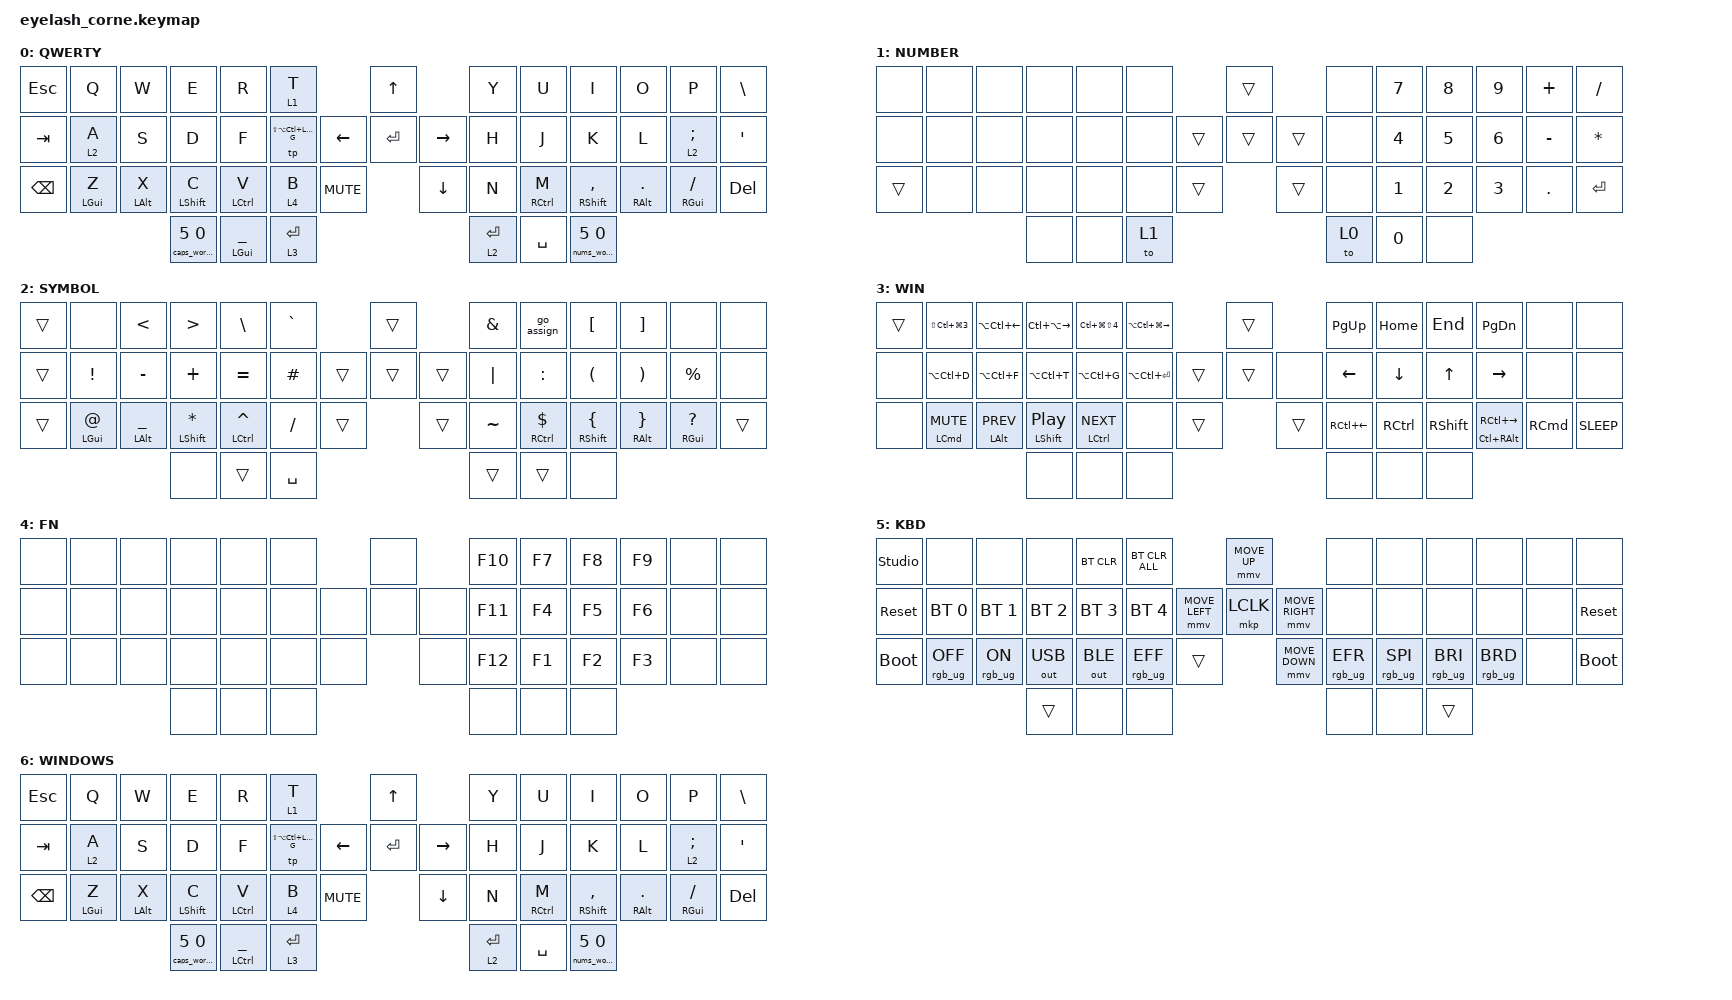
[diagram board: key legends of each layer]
#include "corne_common.dtsi"


    behaviors {
        // Override HMR and HML to add board-specific hold-trigger-key-positions
        HMR: HMR {
            compatible = "zmk,behavior-hold-tap";
            label = "HMR";
            bindings = <&kp>, <&kp>;
            #binding-cells = <2>;
            tapping-term-ms = <200>;
            quick-tap-ms = <175>;
            flavor = "tap-preferred";
            hold-trigger-key-positions = <0 1 2 3 4 5 13 14 15 16 17 18 28 29 30 31 32 33 42 43 44 45 46 47>;
            hold-trigger-on-release;
            require-prior-idle-ms = <150>;
        };

        HML: HML {
            compatible = "zmk,behavior-hold-tap";
            label = "HML";
            bindings = <&kp>, <&kp>;
            #binding-cells = <2>;
            tapping-term-ms = <200>;
            quick-tap-ms = <175>;
            flavor = "tap-preferred";
            hold-trigger-key-positions = <7 8 10 11 12 22 23 24 25 26 27 36 37 38 39 40 41 46 47 45 42 43 44>;
            hold-trigger-on-release;
            require-prior-idle-ms = <150>;
        };
    };

    keymap {
        compatible = "zmk,keymap";

        default_layer {
            display-name = "QWERTY";
            bindings = <
&kp ESCAPE     &kp Q            &kp W            &kp E              &kp R                    &lt 1 T                                             &kp UP                &kp Y        &kp U                 &kp I                   &kp O                  &kp P                 &kp BACKSLASH
&kp TAB        &lt 2 A          &kp S            &kp D              &kp F                    &tp LS(LA(LC(LEFT_GUI))) G                &kp LEFT  &kp ENTER  &kp RIGHT  &kp H        &kp J                 &kp K                   &kp L                  &lt 2 SEMICOLON       &kp SQT
&kp BACKSPACE  &HML LEFT_GUI Z  &HML LEFT_ALT X  &HML LEFT_SHIFT C  &HML LCTRL V             &lt 4 B                     &kp C_MUTE              &kp DOWN              &kp N        &HMR RIGHT_CONTROL M  &HMR RIGHT_SHIFT COMMA  &HMR RIGHT_ALT PERIOD  &HMR RIGHT_GUI SLASH  &kp DELETE
                                                 &caps_word_mo 5 0  &mt LEFT_GUI UNDERSCORE  &lt 3 ENTER                                                               &lt 2 ENTER  &kp SPACE             &nums_word_mo 5 0
            >;

        };

        number {
            bindings = <
&none   &none  &none  &none  &none  &none                    &trans          &none  &kp N7        &kp N8        &kp N9        &kp PLUS    &kp SLASH
&none   &none  &none  &none  &none  &none            &trans  &trans  &trans  &none  &kp NUMBER_4  &kp N5        &kp NUMBER_6  &kp MINUS   &kp ASTERISK
&trans  &none  &none  &none  &none  &none  &trans            &trans          &none  &kp NUMBER_1  &kp NUMBER_2  &kp NUMBER_3  &kp PERIOD  &kp ENTER
                      &none  &none  &to 1                                    &to 0  &kp N0        &none
            >;

            label = "NUMBER";
        };

        symbol {
            bindings = <
&trans  &none             &kp LESS_THAN    &kp GREATER_THAN      &kp BACKSLASH     &kp GRAVE                    &trans          &kp AMPS   &go_assign               &kp LEFT_BRACKET             &kp RIGHT_BRACKET      &none                    &none
&trans  &kp EXCLAMATION   &kp MINUS        &kp PLUS              &kp EQUAL         &kp POUND            &trans  &trans  &trans  &kp PIPE   &kp COLON                &kp LEFT_PARENTHESIS         &kp RIGHT_PARENTHESIS  &kp PERCENT              &none
&trans  &HML LEFT_GUI AT  &HML LALT UNDER  &HML LSHIFT ASTERISK  &HML LCTRL CARET  &kp SLASH  &trans            &trans          &kp TILDE  &HMR RIGHT_CONTROL DLLR  &HMR RIGHT_SHIFT LEFT_BRACE  &HMR RALT RIGHT_BRACE  &HMR RIGHT_GUI QUESTION  &trans
                                           &none                 &trans            &kp SPACE                                    &trans     &trans                   &none
            >;

            label = "SYMBOL";
        };

        win {
            bindings = <
&trans  &kp LS(LC(LG(NUMBER_3)))  &kp LA(LC(LEFT))      &kp LC(LA(RIGHT))             &kp LC(LG(LS(NUMBER_4)))  &kp LA(LC(LG(RIGHT)))                    &trans         &kp PAGE_UP   &kp HOME        &kp END       &kp PAGE_DOWN                 &none     &none
&none   &kp LA(LC(D))             &kp LA(LC(F))         &kp LA(LC(T))                 &kp LA(LC(G))             &kp LA(LC(ENTER))                &trans  &trans  &none  &kp LEFT      &kp DOWN_ARROW  &kp UP_ARROW  &kp RIGHT                     &none     &none
&none   &HML LCMD C_MUTE          &HML LEFT_ALT C_PREV  &HML LEFT_SHIFT C_PLAY_PAUSE  &HML LCTRL C_NEXT         &none                  &trans            &trans         &kp RC(LEFT)  &kp RCTRL       &kp RSHIFT    &HMR LC(RIGHT_ALT) RC(RIGHT)  &kp RCMD  &kp C_SLEEP
                                                        &none                         &none                     &none                                                   &none         &none           &none
            >;

            label = "WIN";
        };

        function {
            bindings = <
&none  &none  &none  &none  &none  &none                  &none         &kp F10  &kp F7  &kp F8  &kp F9  &none  &none
&none  &none  &none  &none  &none  &none           &none  &none  &none  &kp F11  &kp F4  &kp F5  &kp F6  &none  &none
&none  &none  &none  &none  &none  &none  &none           &none         &kp F12  &kp F1  &kp F2  &kp F3  &none  &none
                     &none  &none  &none                                &none    &none   &none
            >;

            label = "FN";
        };

        kbd_ctl {
            display-name = "KBD";
            bindings = <
&studio_unlock  &none            &none           &none         &bt BT_CLR    &bt BT_CLR_ALL                             &mmv MOVE_UP                     &none            &none            &none            &none            &none  &none
&sys_reset      &bt BT_SEL 0     &bt BT_SEL 1    &bt BT_SEL 2  &bt BT_SEL 3  &bt BT_SEL 4               &mmv MOVE_LEFT  &mkp LCLK       &mmv MOVE_RIGHT  &none            &none            &none            &none            &none  &sys_reset
&bootloader     &rgb_ug RGB_OFF  &rgb_ug RGB_ON  &out OUT_USB  &out OUT_BLE  &rgb_ug RGB_EFF  &trans                    &mmv MOVE_DOWN                   &rgb_ug RGB_EFR  &rgb_ug RGB_SPI  &rgb_ug RGB_BRI  &rgb_ug RGB_BRD  &none  &bootloader
                                                 &trans        &none         &none                                                                       &none            &none            &trans
            >;

            label = "KBD";
        };

        windows {
            display-name = "WINDOWS";
            bindings = <
&kp ESCAPE     &kp Q            &kp W            &kp E              &kp R                 &lt 1 T                                             &kp UP                &kp Y        &kp U                 &kp I                   &kp O                  &kp P                 &kp BACKSLASH
&kp TAB        &lt 2 A          &kp S            &kp D              &kp F                 &tp LS(LA(LC(LEFT_GUI))) G                &kp LEFT  &kp ENTER  &kp RIGHT  &kp H        &kp J                 &kp K                   &kp L                  &lt 2 SEMICOLON       &kp SQT
&kp BACKSPACE  &HML LEFT_GUI Z  &HML LEFT_ALT X  &HML LEFT_SHIFT C  &HML LCTRL V          &lt 4 B                     &kp C_MUTE              &kp DOWN              &kp N        &HMR RIGHT_CONTROL M  &HMR RIGHT_SHIFT COMMA  &HMR RIGHT_ALT PERIOD  &HMR RIGHT_GUI SLASH  &kp DELETE
                                                 &caps_word_mo 5 0  &mt LCTRL UNDERSCORE  &lt 3 ENTER                                                               &lt 2 ENTER  &kp SPACE             &nums_word_mo 5 0
            >;

        };
    };
};
